# S32K116 register map
Vendor: NXP; Series: S32K; File version: 1.6
CPU: CM0PLUS r0p0, little endian, MPU, FPU, 2 interrupt priority bits
Registers are 32-bit, read-write, reset 0x0 unless marked. A register's access mark holds for its fields unless they carry their own. Offsets are from the block's base; [hi:lo] are bit positions; {n}, {i} and the like mark numbered series; 'fields as' and 'values as' point back to an identical list.

## S32_NVIC — Nested Vectored Interrupt Controller
Base 0xE000E100
0x00 S32_NVIC_ISER — Interrupt Set Enable Register
  [31:0] SETENA — Interrupt set enable bits
0x80 S32_NVIC_ICER — Interrupt Clear Enable Register
  [31:0] CLRENA — Interrupt clear-enable bits
0x100 S32_NVIC_ISPR — Interrupt Set Pending Register
  [31:0] SETPEND — Interrupt set-pending bits
0x180 S32_NVIC_ICPR — Interrupt Clear Pending Register
  [31:0] CLRPEND — Interrupt clear-pending bits
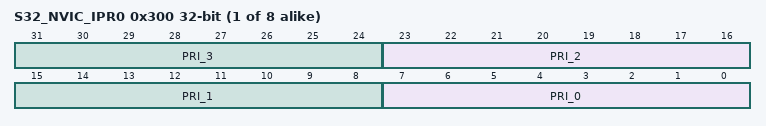
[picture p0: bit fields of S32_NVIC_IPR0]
{0x300+4i} S32_NVIC_IPR{i} (i=0..7) — Interrupt Priority Register n
  [8n+7:8n] PRI_{n} (n=0..3) — Priority of interrupt {n}

## LMEM — Local Memory Controller
Base 0xE0082000; register names take the prefix LMEM_
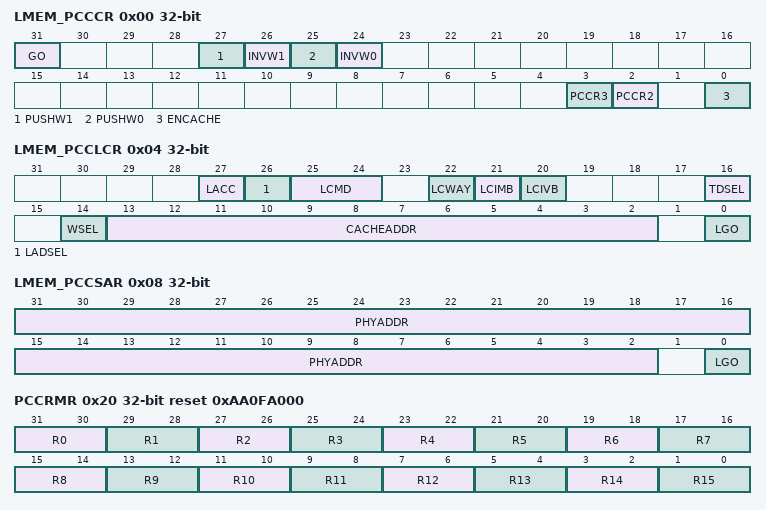
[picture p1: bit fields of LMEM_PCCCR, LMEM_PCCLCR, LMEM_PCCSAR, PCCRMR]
0x00 LMEM_PCCCR — Cache control register
  [31] GO — Initiate Cache Command
    0=Write: no effect. Read: no cache command active.; 1=Write: initiate command indicated by bits 27-24. Read: cache command active.
  [27] PUSHW1 — Push Way 1
    0=No operation; 1=When setting the GO bit, push all modified lines in way 1
  [26] INVW1 — Invalidate Way 1
    0=No operation; 1=When setting the GO bit, invalidate all lines in way 1
  [25] PUSHW0 — Push Way 0
    0=No operation; 1=When setting the GO bit, push all modified lines in way 0
  [24] INVW0 — Invalidate Way 0
    0=No operation; 1=When setting the GO bit, invalidate all lines in way 0
  [3] PCCR3 — Forces no allocation on cache misses (must also have PCCR2 asserted)
  [2] PCCR2 — Forces all cacheable spaces to write through
  [0] ENCACHE — Cache enable
    0=Cache disabled; 1=Cache enabled
0x04 LMEM_PCCLCR — Cache line control register
  [27] LACC — Line access type
    0=Read; 1=Write
  [26] LADSEL — Line Address Select
    0=Cache address; 1=Physical address
  [25:24] LCMD — Line Command
    0=Search and read or write; 1=Invalidate; 2=Push; 3=Clear
  [22] LCWAY — Line Command Way
  [21] LCIMB — Line Command Initial Modified Bit
  [20] LCIVB — Line Command Initial Valid Bit
  [16] TDSEL — Tag/Data Select
    0=Data; 1=Tag
  [14] WSEL — Way select
    0=Way 0; 1=Way 1
  [13:2] CACHEADDR — Cache address
  [0] LGO — Initiate Cache Line Command
    0=Write: no effect. Read: no line command active.; 1=Write: initiate line command indicated by bits 27-24. Read: line command active.
0x08 LMEM_PCCSAR — Cache search address register
  [31:2] PHYADDR — Physical Address
  [0] LGO — Initiate Cache Line Command
    0=Write: no effect. Read: no line command active.; 1=Write: initiate line command indicated by bits CLCR[27:24]. Read: line command active.
0x0C LMEM_PCCCVR — Cache read/write value register
  [31:0] DATA — Cache read/write Data
0x20 PCCRMR reset 0xAA0FA000 — Cache regions mode register
  [all] fields
    0=Non-cacheable; 1=Non-cacheable; 2=Write-through; 3=Write-back
  [31-2n:30-2n] R{n} (n=0..15) — Region {n} mode

## MTB_DWT — MTB data watchpoint and trace
Base 0xF0001000; register names take the prefix MTB_DWT_
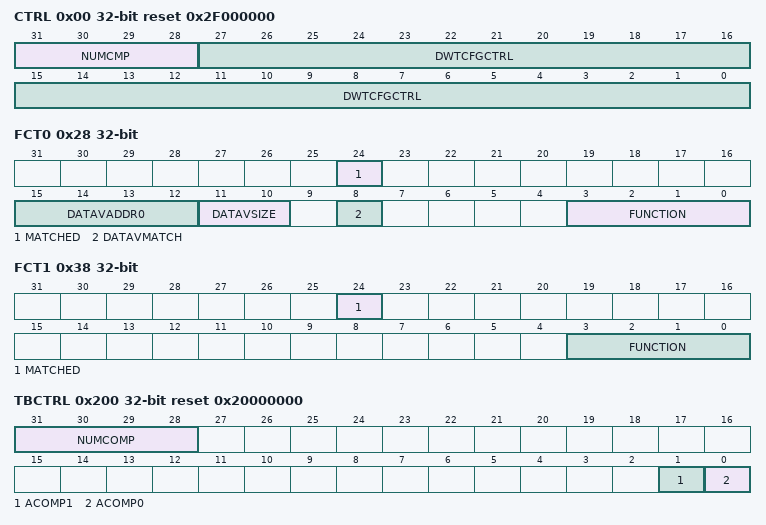
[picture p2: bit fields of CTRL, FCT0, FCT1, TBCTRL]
0x00 CTRL ro reset 0x2F000000 — MTB DWT Control Register
  [31:28] NUMCMP — Number of comparators
  [27:0] DWTCFGCTRL — DWT configuration controls
{0x20+0x10*i} COMP{i} (i=0..1) — MTB_DWT Comparator Register
  [31:0] COMP — Reference value for comparison
{0x24+0x10*i} MASK{i} (i=0..1) — MTB_DWT Comparator Mask Register
  [4:0] MASK
0x28 FCT0 — MTB_DWT Comparator Function Register 0
  [24] MATCHED ro — Comparator match
    0=No match; 1=Match occurred
  [15:12] DATAVADDR0 — Data Value Address 0
  [11:10] DATAVSIZE — Data Value Size
    0=Byte; 1=Halfword; 2=Word; 3=Reserved. Any attempts to use this value results in UNPREDICTABLE behavior.
  [8] DATAVMATCH — Data Value Match
    0=Perform address comparison; 1=Perform data value comparison
  [3:0] FUNCTION
    0=Disabled; 4=Instruction fetch; 5=Data operand read; 6=Data operand write; 7=Data operand (read + write)
0x38 FCT1 — MTB_DWT Comparator Function Register 1
  [24] MATCHED ro — Comparator match
    0=No match; 1=Match occurred
  [3:0] FUNCTION
    values as FCT0.FUNCTION
0x200 TBCTRL reset 0x20000000 — MTB_DWT Trace Buffer Control Register
  [31:28] NUMCOMP ro — Number of Comparators
  [1] ACOMP1 — Action based on Comparator 1 match
    0=Trigger TSTOP based on the assertion of MTBDWT_FCT1[MATCHED]; 1=Trigger TSTART based on the assertion of MTBDWT_FCT1[MATCHED]
  [0] ACOMP0 — Action based on Comparator 0 match
    0=Trigger TSTOP based on the assertion of MTBDWT_FCT0[MATCHED]; 1=Trigger TSTART based on the assertion of MTBDWT_FCT0[MATCHED]
0xFC8 DEVICECFG ro — Device Configuration Register
0xFCC DEVICETYPID ro reset 0x4 — Device Type Identifier Register
0xFD0 PERIPHID{x} (x=4,5,6,7,0,1,2,3; step 0x4) ro reset not defined — Peripheral ID Register
  [31:0] PERIPHID
{0xFF0+4i} COMPID{i} (i=0..3) ro reset not defined — Component ID Register
  [31:0] COMPID — Component ID

## Notices in the file
Redistribution and use in source and binary forms, with or without modification,
are permitted provided that the following conditions are met:
o Redistributions of source code must retain the above copyright notice, this list
of conditions and the following disclaimer.
o Redistributions in binary form must reproduce the above copyright notice, this
list of conditions and the following disclaimer in the documentation and/or
other materials provided with the distribution.
o Neither the name of Freescale Semiconductor, Inc. nor the names of its
contributors may be used to endorse or promote products derived from this
software without specific prior written permission.
THIS SOFTWARE IS PROVIDED BY THE COPYRIGHT HOLDERS AND CONTRIBUTORS "AS IS" AND
ANY EXPRESS OR IMPLIED WARRANTIES, INCLUDING, BUT NOT LIMITED TO, THE IMPLIED
WARRANTIES OF MERCHANTABILITY AND FITNESS FOR A PARTICULAR PURPOSE ARE
DISCLAIMED. IN NO EVENT SHALL THE COPYRIGHT HOLDER OR CONTRIBUTORS BE LIABLE FOR
ANY DIRECT, INDIRECT, INCIDENTAL, SPECIAL, EXEMPLARY, OR CONSEQUENTIAL DAMAGES
(INCLUDING, BUT NOT LIMITED TO, PROCUREMENT OF SUBSTITUTE GOODS OR SERVICES;
LOSS OF USE, DATA, OR PROFITS; OR BUSINESS INTERRUPTION) HOWEVER CAUSED AND ON
ANY THEORY OF LIABILITY, WHETHER IN CONTRACT, STRICT LIABILITY, OR TORT
(INCLUDING NEGLIGENCE OR OTHERWISE) ARISING IN ANY WAY OUT OF THE USE OF THIS
SOFTWARE, EVEN IF ADVISED OF THE POSSIBILITY OF SUCH DAMAGE.
